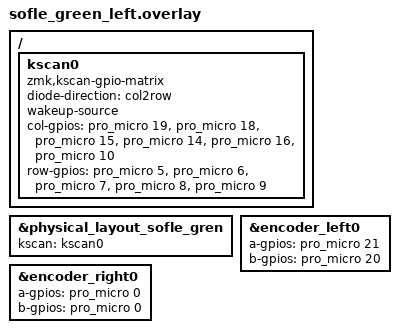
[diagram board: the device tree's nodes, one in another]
#include "sofle_gren.dtsi"

/ {
    kscan0: kscan0 {
        compatible = "zmk,kscan-gpio-matrix";
                diode-direction = "col2row";
        wakeup-source;

        col-gpios
            = <&pro_micro 19 GPIO_ACTIVE_HIGH>
            , <&pro_micro 18 GPIO_ACTIVE_HIGH>
            , <&pro_micro 15 GPIO_ACTIVE_HIGH>
            , <&pro_micro 14 GPIO_ACTIVE_HIGH>
            , <&pro_micro 16 GPIO_ACTIVE_HIGH>
            , <&pro_micro 10 GPIO_ACTIVE_HIGH>
            ;

        row-gpios
            = <&pro_micro 5 (GPIO_ACTIVE_HIGH | GPIO_PULL_DOWN)>
            , <&pro_micro 6 (GPIO_ACTIVE_HIGH | GPIO_PULL_DOWN)>
            , <&pro_micro 7 (GPIO_ACTIVE_HIGH | GPIO_PULL_DOWN)>
            , <&pro_micro 8 (GPIO_ACTIVE_HIGH | GPIO_PULL_DOWN)>
            , <&pro_micro 9 (GPIO_ACTIVE_HIGH | GPIO_PULL_DOWN)>
            ;
    };
};

&physical_layout_sofle_gren {
    kscan = <&kscan0>;
};

&encoder_left0 {
    a-gpios = <&pro_micro 21 (GPIO_ACTIVE_HIGH | GPIO_PULL_UP)>;
    b-gpios = <&pro_micro 20 (GPIO_ACTIVE_HIGH | GPIO_PULL_UP)>;
    status = "okay";
};

// Assigning dummy pins to other part's encoders
// just to satisfy the devicetree requirements.
// No code will be compiled for these disabled encoders.
&encoder_right0 {
    a-gpios = <&pro_micro 0 (GPIO_ACTIVE_HIGH | GPIO_PULL_UP)>;
    b-gpios = <&pro_micro 0 (GPIO_ACTIVE_HIGH | GPIO_PULL_UP)>;
};

/* &spi3 { */
/*     compatible = "nordic,nrf-spim"; */
/*     status = "okay"; */
/**/
/*     led_strip: ws2812@0 { */
/*         compatible = "worldsemi,ws2812-spi"; */
/*         reg = <0>; */
/*         spi-max-frequency = <4000000>; */
/**/
/*         chain-length = <12>; */
/**/
/*         spi-one-frame = <0x70>; */
/*         spi-zero-frame = <0x40>; */
/**/
/*         color-mapping = < */
/*             LED_COLOR_ID_GREEN */
/*             LED_COLOR_ID_RED */
/*             LED_COLOR_ID_BLUE */
/*         >; */
/*     }; */
/* }; */
